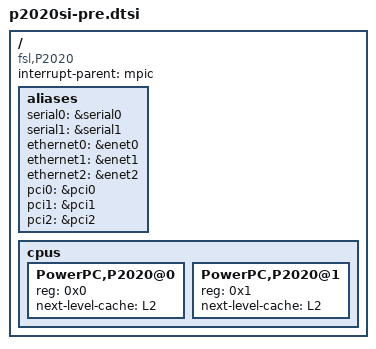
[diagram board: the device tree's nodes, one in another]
/dts-v1/;
/include/ "e500v2_power_isa.dtsi"
/ {
	compatible = "fsl,P2020";
	#address-cells = <2>;
	#size-cells = <2>;
	interrupt-parent = <&mpic>;
	aliases {
		serial0 = &serial0;
		serial1 = &serial1;
		ethernet0 = &enet0;
		ethernet1 = &enet1;
		ethernet2 = &enet2;
		pci0 = &pci0;
		pci1 = &pci1;
		pci2 = &pci2;
	};
	cpus {
		#address-cells = <1>;
		#size-cells = <0>;
		PowerPC,P2020@0 {
			device_type = "cpu";
			reg = <0x0>;
			next-level-cache = <&L2>;
		};
		PowerPC,P2020@1 {
			device_type = "cpu";
			reg = <0x1>;
			next-level-cache = <&L2>;
		};
	};
};
